# CC1314R10 register map
File version: 1.0
CPU: CM33 1.0, other endian, MPU, FPU, 3 interrupt priority bits
Registers are 32-bit, read-write, reset 0x0 unless marked. A register's access mark holds for its fields unless they carry their own. Offsets are from the block's base; [hi:lo] are bit positions; {n}, {i} and the like mark numbered series; 'fields as' and 'values as' point back to an identical list; <NAME> marks a mode.

## AUX_TIMER2 — AUX Timer2 (AUX_TIMER2) offers flexible: - generation of waveforms and events. - capture of signal period and duty cycle. - generation of single clock pulse. It consists of a: - 16-bit counter. - 4 capture compare channels. - 4 event outputs, which are mapped to AUX event bus, see EVCTL. Each channel subscribes to the asynchronous AUX event bus. They can control one or more event outputs in both capture and compare modes. AUX_SYSIF:TIMER2CLKCTL.SRC selects clock source for the timer.
Base 0x400C3000
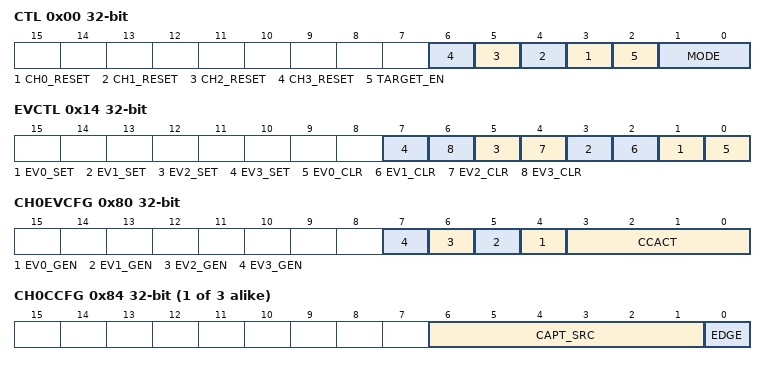
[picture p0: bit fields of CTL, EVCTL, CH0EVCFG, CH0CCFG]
0x00 CTL — Timer Control
  [n+3] CH{n}_RESET (n=0..3) — [{n+3}:{n+3}] Channel {n} reset. 0: No effect. 1: Reset CH{n}CC, CH{n}PCC, CH{n}EVCFG, and CH{n}CCFG. Read returns 0.
  [2] TARGET_EN — [2:2] Select counter target value. You must select TARGET to use shadow target functionality.
    1=TARGET (TARGET.VALUE); 0=CNTR_MAX (65535)
  [1:0] MODE — [1:0] Timer mode control. The timer restarts from 0 when you set MODE to UP_ONCE, UP_PER, or UPDWN_PER. When you write MODE all internally queued updates to [CHnCC.*] and TARGET clear.
    3=UPDWN_PER (Count up and down periodically. The timer counts from 0 to target value and back to 0, repeatedly. Period = (target value * 2) * timer clock period); 2=UP_PER (Count up periodically. The timer increments from 0 to target value, repeatedly. Period = (target value + 1) * timer clock period); 1=UP_ONCE (Count up once. The timer increments from 0 to target value, then stops and sets MODE to DIS.); 0=DIS (Disable timer. Updates to counter, channels, and events stop.)
0x04 TARGET — Target User defined counter target.
  [15:0] VALUE — [15:0] 16 bit user defined counter target value, which is used when selected by CTL.TARGET_EN.
0x08 SHDWTARGET — Shadow Target
  [15:0] VALUE — [15:0] Target value for next counter period. The timer copies VALUE to TARGET.VALUE when CNTR.VALUE becomes 0. The copy does not happen when you restart the timer. This is useful to avoid period jitter in PWM applications with time-varying period, sometimes referenced as phase corrected PWM.
0x0C CNTR — Counter
  [15:0] VALUE ro — [15:0] 16 bit current counter value.
0x10 PRECFG — Clock Prescaler Configuration
  [7:0] CLKDIV — [7:0] Clock division. CLKDIV determines the timer clock frequency for counter, synchronization, and timer event updates. The timer clock frequency is the clock selected by AUX_SYSIF:TIMER2CLKCTL.SRC divided by (CLKDIV + 1). This inverse is the timer clock period. 0x00: Divide by 1. 0x01: Divide by 2. ... 0xFF: Divide by 256.
0x14 EVCTL — Event Control Set and clear individual events manually. Manual update of an event takes priority over automatic channel updates to the same event. You cannot set and clear an event at the same time, such requests will be neglected. An event can be automatically cleared, set, toggled, or pulsed by each channel, listed in decreasing order of priority. The action with highest priority happens when multiple channels want to update an event at the same time. The four events connect to the asynchronous AUX event bus: - Event 0 connects to AUX_EVCTL:EVSTAT3.AUX_TIMER2_EV0. - Event 1 connects to AUX_EVCTL:EVSTAT3.AUX_TIMER2_EV1. - Event 2 connects to AUX_EVCTL:EVSTAT3.AUX_TIMER2_EV2. - Event 3 connects to AUX_EVCTL:EVSTAT3.AUX_TIMER2_EV3.
  [2n+1] EV{n}_SET wo (n=0..3) — [{2n+1}:{2n+1}] Set event {n}. Write 1 to set event {n}.
  [2n] EV{n}_CLR wo (n=0..3) — [{2n}:{2n}] Clear event {n}. Write 1 to clear event {n}.
0x18 PULSETRIG — Pulse Trigger
  [0] TRIG wo — [0:0] Pulse trigger. Write 1 to generate a pulse to AUX_EVCTL:EVSTAT3.AUX_TIMER2_PULSE. Pulse width equals the duty cycle of AUX_SYSIF:TIMER2CLKCTL.SRC.
0x80 CH0EVCFG — Channel 0 Event Configuration This register configures channel function and enables event outputs. Each channel has an edge-detection circuit with memory. The circuit is: - enabled while CCACT selects a capture function and CTL.MODE is different from DIS. - flushed while CCACT selects a capture function and you change CTL.MODE from DIS to another mode. The flush action uses two AUX_SYSIF:TIMER2CLKCTL.SRC clock periods. It prevents capture events caused by expired signal values stored in the edge-detection circuit.
  [n+4] EV{n}_GEN (n=0..3) — [{n+4}:{n+4}] Event {n} enable. 0: Channel 0 does not control event {n}. 1: Channel 0 controls event {n}. When 0 < CCACT < 8, EV{n}_GEN becomes zero after a capture or compare event.
  [3:0] CCACT — [3:0] Capture-Compare action. Capture-Compare action defines 15 different channel functions that utilize capture, compare, and zero events.
    15=PULSE_ON_CMP (Pulse on compare repeatedly. Channel function sequence: - Pulse enabled events when CH0CC.VALUE = CNTR.VALUE. The event is high for two timer clock periods.); 14=TGL_ON_CMP (Toggle on compare repeatedly. Channel function sequence: - Toggle enabled events when CH0CC.VALUE = CNTR.VALUE.); 13=SET_ON_CMP (Set on compare repeatedly. Channel function sequence: - Set enabled events when CH0CC.VALUE = CNTR.VALUE.); 12=CLR_ON_CMP (Clear on compare repeatedly. Channel function sequence: - Clear enabled events when CH0CC.VALUE = CNTR.VALUE.); 11=SET_ON_0_TGL_ON_CMP (Set on zero, toggle on compare repeatedly. Channel function sequence: - Set enabled events when CNTR.VALUE = 0. - Toggle enabled events when CH0CC.VALUE = CNTR.VALUE. Set CTL.MODE to UP_PER for edge-aligned PWM generation. Duty cycle is given by: When CH0CC.VALUE <= TARGET.VALUE: Duty cycle = CH0CC.VALUE / ( TARGET.VALUE + 1 ). When CH0CC.VALUE > TARGET.VALUE: Duty cycle = 1. Enabled events are cleared when CH0CC.VALUE = 0 and CNTR.VALUE = 0.); 10=CLR_ON_0_TGL_ON_CMP (Clear on zero, toggle on compare repeatedly. Channel function sequence: - Clear enabled events when CNTR.VALUE = 0. - Toggle enabled events when CH0CC.VALUE = CNTR.VALUE. Set CTL.MODE to UPDWN_PER for center-aligned PWM generation. Duty cycle is given by: When CH0CC.VALUE <= TARGET.VALUE: Duty cycle = 1 - ( CH0CC.VALUE / TARGET.VALUE ). When CH0CC.VALUE > TARGET.VALUE: Duty cycle = 0. Enabled events are set when CH0CC.VALUE = 0 and CNTR.VALUE = 0.); 9=SET_ON_CAPT (Set on capture repeatedly. Channel function sequence: - Set enabled events on capture event and copy CNTR.VALUE to CH0CC.VALUE. Primary use scenario is to select this function before you start the timer. Follow these steps if you need to select this function while CTL.MODE is different from DIS: - Select this function with no event enable. - Configure CH0CCFG (optional). - Wait for three timer clock periods as defined in PRECFG before you enable events. These steps prevent capture events caused by expired signal values in edge-detection circuit.); 8=PER_PULSE_WIDTH_MEAS (Period and pulse width measurement. Continuously capture period and pulse width of the signal selected by CH0CCFG.CAPT_SRC relative to the signal edge given by CH0CCFG.EDGE. Set enabled events when CH0CC.VALUE contains signal period and CH0PCC.VALUE contains signal pulse width. Notes: - Make sure that you configure CH0CCFG.CAPT_SRC and CCACT when CTL.MODE equals DIS, then set CTL.MODE to UP_ONCE or UP_PER. - The counter restarts in the selected timer mode when CH0CC.VALUE contains the signal period. - If more than one channel uses this function, the channels will perform this function one at a time. The channel with lowest number has priority and performs the function first. Next measurement starts when current measurement completes successfully or times out. A timeout occurs when counter equals target. - If you want to observe a timeout event configure another channel to SET_ON_CAPT. Signal property requirements: - Signal Period >= 2 * ( 1 + PRECFG.CLKDIV ) * timer clock period. - Signal Period <= 65535 * (1 + PRECFG.CLKDIV ) * timer clock period. - Signal low and high phase >= (1 + PRECFG.CLKDIV ) * timer clock period.); 7=PULSE_ON_CMP_DIS (Pulse on compare, and then disable channel. Channel function sequence: - Pulse enabled events when CH0CC.VALUE = CNTR.VALUE. - Disable channel. The event is high for two timer clock periods.); 6=TGL_ON_CMP_DIS (Toggle on compare, and then disable channel. Channel function sequence: - Toggle enabled events when CH0CC.VALUE = CNTR.VALUE. - Disable channel.); 5=SET_ON_CMP_DIS (Set on compare, and then disable channel. Channel function sequence: - Set enabled events when CH0CC.VALUE = CNTR.VALUE. - Disable channel.); 4=CLR_ON_CMP_DIS (Clear on compare, and then disable channel. Channel function sequence: - Clear enabled events when CH0CC.VALUE = CNTR.VALUE. - Disable channel.); 3=SET_ON_0_TGL_ON_CMP_DIS (Set on zero, toggle on compare, and then disable channel. Channel function sequence: - Set enabled events when CNTR.VALUE = 0. - Toggle enabled events when CH0CC.VALUE = CNTR.VALUE. - Disable channel. Enabled events are cleared when CH0CC.VALUE = 0 and CNTR.VALUE = 0.); 2=CLR_ON_0_TGL_ON_CMP_DIS (Clear on zero, toggle on compare, and then disable channel. Channel function sequence: - Clear enabled events when CNTR.VALUE = 0. - Toggle enabled events when CH0CC.VALUE = CNTR.VALUE. - Disable channel. Enabled events are set when CH0CC.VALUE = 0 and CNTR.VALUE = 0.); 1=SET_ON_CAPT_DIS (Set on capture, and then disable channel. Channel function sequence: - Set enabled events on capture event and copy CNTR.VALUE to CH0CC.VALUE. - Disable channel. Primary use scenario is to select this function before you start the timer. Follow these steps if you need to select this function while CTL.MODE is different from DIS: - Set CCACT to SET_ON_CAPT with no event enable. - Configure CH0CCFG (optional). - Wait for three timer clock periods as defined in PRECFG before you set CCACT to SET_ON_CAPT_DIS. Event enable is optional. These steps prevent capture events caused by expired signal values in edge-detection circuit.); 0=DIS (Disable channel.)
{0x84+0x10*i} CH{i}CCFG (i=0..2) — Channel {i} Capture Configuration
  [6:1] CAPT_SRC — [6:1] Select capture signal source from the asynchronous AUX event bus. The selected signal enters the edge-detection circuit. False capture events can occur when: - the edge-detection circuit contains expired signal samples and the circuit is enabled without flush as described in CH{i}EVCFG - this register is reconfigured while CTL.MODE is different from DIS. You can avoid false capture events. When wanted channel function is: - SET_ON_CAPT_DIS, see description for SET_ON_CAPT_DIS in CH{i}EVCFG.CCACT. - SET_ON_CAPT, see description for SET_ON_CAPT in CH{i}EVCFG.CCACT. - PER_PULSE_WIDTH_MEAS, see description for PER_PULSE_WIDTH_MEAS in CH{i}EVCFG.CCACT. If you write a non-enumerated value the behavior is identical to NO_EVENT. The written value is returned when read.
    63=NO_EVENT; 61=AUX_SMPH_AUTOTAKE_DONE (AUX_EVCTL:EVSTAT3.AUX_SMPH_AUTOTAKE_DONE); 60=AUX_ADC_FIFO_NOT_EMPTY (AUX_EVCTL:EVSTAT3.AUX_ADC_FIFO_NOT_EMPTY); 59=AUX_ADC_FIFO_ALMOST_FULL (AUX_EVCTL:EVSTAT3.AUX_ADC_FIFO_ALMOST_FULL); 58=AUX_ADC_IRQ (AUX_EVCTL:EVSTAT3.AUX_ADC_IRQ); 57=AUX_ADC_DONE (AUX_EVCTL:EVSTAT3.AUX_ADC_DONE); 56=AUX_ISRC_RESET_N (AUX_EVCTL:EVSTAT3.AUX_ISRC_RESET_N); 55=AUX_TDC_DONE (AUX_EVCTL:EVSTAT3.AUX_TDC_DONE); 54=AUX_TIMER0_EV (AUX_EVCTL:EVSTAT3.AUX_TIMER0_EV); 53=AUX_TIMER1_EV (AUX_EVCTL:EVSTAT3.AUX_TIMER1_EV); {v}=AUX_TIMER2_EV{v-48} (AUX_EVCTL:EVSTAT3.AUX_TIMER2_EV{v-48}) (v=48..51); 47=AUX_COMPB (AUX_EVCTL:EVSTAT2.AUX_COMPB); 46=AUX_COMPA (AUX_EVCTL:EVSTAT2.AUX_COMPA); 45=MCU_OBSMUX1 (AUX_EVCTL:EVSTAT2.MCU_OBSMUX1); 44=MCU_OBSMUX0 (AUX_EVCTL:EVSTAT2.MCU_OBSMUX0); 43=MCU_EV (AUX_EVCTL:EVSTAT2.MCU_EV); 42=ACLK_REF (AUX_EVCTL:EVSTAT2.ACLK_REF); 41=VDDR_RECHARGE (AUX_EVCTL:EVSTAT2.VDDR_RECHARGE); 40=MCU_ACTIVE (AUX_EVCTL:EVSTAT2.MCU_ACTIVE); 39=PWR_DWN (AUX_EVCTL:EVSTAT2.PWR_DWN); 38=SCLK_LF (AUX_EVCTL:EVSTAT2.SCLK_LF); 37=AON_BATMON_TEMP_UPD (AUX_EVCTL:EVSTAT2.AON_BATMON_TEMP_UPD); 36=AON_BATMON_BAT_UPD (AUX_EVCTL:EVSTAT2.AON_BATMON_BAT_UPD); 35=AON_RTC_4KHZ (AUX_EVCTL:EVSTAT2.AON_RTC_4KHZ); 34=AON_RTC_CH2_DLY (AUX_EVCTL:EVSTAT2.AON_RTC_CH2_DLY); 33=AON_RTC_CH2 (AUX_EVCTL:EVSTAT2.AON_RTC_CH2); 32=MANUAL_EV (AUX_EVCTL:EVSTAT2.MANUAL_EV); {v}=AUXIO{v} (AUX_EVCTL:EVSTAT1.AUXIO{v}) (v=16..31); {v}=AUXIO{v} (AUX_EVCTL:EVSTAT0.AUXIO{v}) (v=0..15)
  [0] EDGE — [0:0] Edge configuration. Channel captures counter value at selected edge on signal source selected by CAPT_SRC. See CH{i}EVCFG.CCACT.
    1=RISING (Capture CNTR.VALUE at rising edge of CAPT_SRC.); 0=FALLING (Capture CNTR.VALUE at falling edge of CAPT_SRC.)
{0x88+0x10*i} CH{i}PCC (i=0..3) — Channel {i} Pipeline Capture Compare
  [15:0] VALUE — [15:0] Pipeline Capture Compare value. 16-bit user defined pipeline compare value or channel-updated capture value. Compare mode: An update of VALUE will be transferred to CH{i}CC.VALUE when the next CNTR.VALUE is zero and CTL.MODE is different from DIS. This is useful for PWM generation and prevents jitter on the edges of the generated signal. Capture mode: When CH{i}EVCFG.CCACT equals PER_PULSE_WIDTH_MEAS then VALUE contains the width of the low or high phase of the selected signal. This is specified by CH{i}CCFG.EDGE and CH{i}CCFG.CAPT_SRC.
{0x8C+0x10*i} CH{i}CC (i=0..3) — Channel {i} Capture Compare
  [15:0] VALUE — [15:0] Capture Compare value. 16-bit user defined compare value or channel-updated capture value. Compare mode: VALUE is compared against CNTR.VALUE and an event is generated as specified by CH{i}EVCFG.CCACT when these are equal. Capture mode: The current counter value is stored in VALUE when a capture event occurs. CH{i}EVCFG.CCACT determines if VALUE is a signal period or a regular capture value.
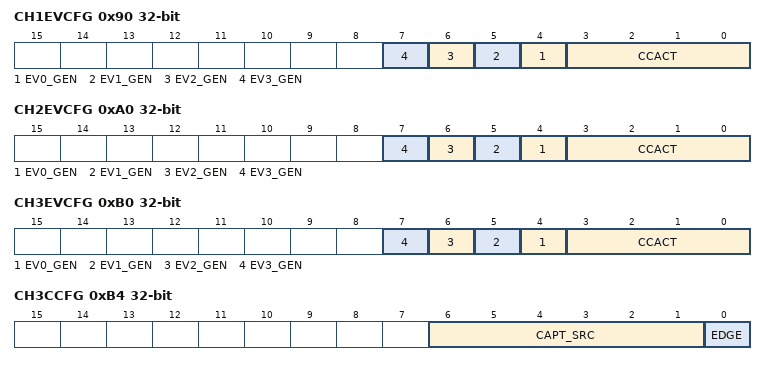
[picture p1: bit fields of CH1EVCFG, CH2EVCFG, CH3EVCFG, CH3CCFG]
0x90 CH1EVCFG — Channel 1 Event Configuration This register configures channel function and enables event outputs. Each channel has an edge-detection circuit with memory. The circuit is: - enabled while CCACT selects a capture function and CTL.MODE is different from DIS. - flushed while CCACT selects a capture function and you change CTL.MODE from DIS to another mode. The flush action uses two AUX_SYSIF:TIMER2CLKCTL.SRC clock periods. It prevents capture events caused by expired signal values stored in the edge-detection circuit.
  [n+4] EV{n}_GEN (n=0..3) — [{n+4}:{n+4}] Event {n} enable. 0: Channel 1 does not control event {n}. 1: Channel 1 controls event {n}. When 0 < CCACT < 8, EV{n}_GEN becomes zero after a capture or compare event.
  [3:0] CCACT — [3:0] Capture-Compare action. Capture-Compare action defines 15 different channel functions that utilize capture, compare, and zero events.
    15=PULSE_ON_CMP (Pulse on compare repeatedly. Channel function sequence: - Pulse enabled events when CH1CC.VALUE = CNTR.VALUE. The event is high for two timer clock periods.); 14=TGL_ON_CMP (Toggle on compare repeatedly. Channel function sequence: - Toggle enabled events when CH1CC.VALUE = CNTR.VALUE.); 13=SET_ON_CMP (Set on compare repeatedly. Channel function sequence: - Set enabled events when CH1CC.VALUE = CNTR.VALUE.); 12=CLR_ON_CMP (Clear on compare repeatedly. Channel function sequence: - Clear enabled events when CH1CC.VALUE = CNTR.VALUE.); 11=SET_ON_0_TGL_ON_CMP (Set on zero, toggle on compare repeatedly. Channel function sequence: - Set enabled events when CNTR.VALUE = 0. - Toggle enabled events when CH1CC.VALUE = CNTR.VALUE. Set CTL.MODE to UP_PER for edge-aligned PWM generation. Duty cycle is given by: When CH1CC.VALUE <= TARGET.VALUE: Duty cycle = CH1CC.VALUE / ( TARGET.VALUE + 1 ). When CH1CC.VALUE > TARGET.VALUE: Duty cycle = 1. Enabled events are cleared when CH1CC.VALUE = 0 and CNTR.VALUE = 0.); 10=CLR_ON_0_TGL_ON_CMP (Clear on zero, toggle on compare repeatedly. Channel function sequence: - Clear enabled events when CNTR.VALUE = 0. - Toggle enabled events when CH1CC.VALUE = CNTR.VALUE. Set CTL.MODE to UPDWN_PER for center-aligned PWM generation. Duty cycle is given by: When CH1CC.VALUE <= TARGET.VALUE: Duty cycle = 1 - ( CH1CC.VALUE / TARGET.VALUE ). When CH1CC.VALUE > TARGET.VALUE: Duty cycle = 0. Enabled events are set when CH1CC.VALUE = 0 and CNTR.VALUE = 0.); 9=SET_ON_CAPT (Set on capture repeatedly. Channel function sequence: - Set enabled events on capture event and copy CNTR.VALUE to CH1CC.VALUE. Primary use scenario is to select this function before you start the timer. Follow these steps if you need to select this function while CTL.MODE is different from DIS: - Select this function with no event enable. - Configure CH1CCFG (optional). - Wait for three timer clock periods as defined in PRECFG before you enable events. These steps prevent capture events caused by expired signal values in edge-detection circuit.); 8=PER_PULSE_WIDTH_MEAS (Period and pulse width measurement. Continuously capture period and pulse width of the signal selected by CH1CCFG.CAPT_SRC relative to the signal edge given by CH1CCFG.EDGE. Set enabled events when CH1CC.VALUE contains signal period and CH1PCC.VALUE contains signal pulse width. Notes: - Make sure that you configure CH1CCFG.CAPT_SRC and CCACT when CTL.MODE equals DIS, then set CTL.MODE to UP_ONCE or UP_PER. - The counter restarts in the selected timer mode when CH1CC.VALUE contains the signal period. - If more than one channel uses this function, the channels will perform this function one at a time. The channel with lowest number has priority and performs the function first. Next measurement starts when current measurement completes successfully or times out. A timeout occurs when counter equals target. - If you want to observe a timeout event configure another channel to SET_ON_CAPT. Signal property requirements: - Signal Period >= 2 * ( 1 + PRECFG.CLKDIV ) * timer clock period. - Signal Period <= 65535 * (1 + PRECFG.CLKDIV ) * timer clock period. - Signal low and high phase >= (1 + PRECFG.CLKDIV ) * timer clock period.); 7=PULSE_ON_CMP_DIS (Pulse on compare, and then disable channel. Channel function sequence: - Pulse enabled events when CH1CC.VALUE = CNTR.VALUE. - Disable channel. The event is high for two timer clock periods.); 6=TGL_ON_CMP_DIS (Toggle on compare, and then disable channel. Channel function sequence: - Toggle enabled events when CH1CC.VALUE = CNTR.VALUE. - Disable channel.); 5=SET_ON_CMP_DIS (Set on compare, and then disable channel. Channel function sequence: - Set enabled events when CH1CC.VALUE = CNTR.VALUE. - Disable channel.); 4=CLR_ON_CMP_DIS (Clear on compare, and then disable channel. Channel function sequence: - Clear enabled events when CH1CC.VALUE = CNTR.VALUE. - Disable channel.); 3=SET_ON_0_TGL_ON_CMP_DIS (Set on zero, toggle on compare, and then disable channel. Channel function sequence: - Set enabled events when CNTR.VALUE = 0. - Toggle enabled events when CH1CC.VALUE = CNTR.VALUE. - Disable channel. Enabled events are cleared when CH1CC.VALUE = 0 and CNTR.VALUE = 0.); 2=CLR_ON_0_TGL_ON_CMP_DIS (Clear on zero, toggle on compare, and then disable channel. Channel function sequence: - Clear enabled events when CNTR.VALUE = 0. - Toggle enabled events when CH1CC.VALUE = CNTR.VALUE. - Disable channel. Enabled events are set when CH1CC.VALUE = 0 and CNTR.VALUE = 0.); 1=SET_ON_CAPT_DIS (Set on capture, and then disable channel. Channel function sequence: - Set enabled events on capture event and copy CNTR.VALUE to CH1CC.VALUE. - Disable channel. Primary use scenario is to select this function before you start the timer. Follow these steps if you need to select this function while CTL.MODE is different from DIS: - Set CCACT to SET_ON_CAPT with no event enable. - Configure CH1CCFG (optional). - Wait for three timer clock periods as defined in PRECFG before you set CCACT to SET_ON_CAPT_DIS. Event enable is optional. These steps prevent capture events caused by expired signal values in edge-detection circuit.); 0=DIS (Disable channel.)
0xA0 CH2EVCFG — Channel 2 Event Configuration This register configures channel function and enables event outputs. Each channel has an edge-detection circuit with memory. The circuit is: - enabled while CCACT selects a capture function and CTL.MODE is different from DIS. - flushed while CCACT selects a capture function and you change CTL.MODE from DIS to another mode. The flush action uses two AUX_SYSIF:TIMER2CLKCTL.SRC clock periods. It prevents capture events caused by expired signal values stored in the edge-detection circuit.
  [n+4] EV{n}_GEN (n=0..3) — [{n+4}:{n+4}] Event {n} enable. 0: Channel 2 does not control event {n}. 1: Channel 2 controls event {n}. When 0 < CCACT < 8, EV{n}_GEN becomes zero after a capture or compare event.
  [3:0] CCACT — [3:0] Capture-Compare action. Capture-Compare action defines 15 different channel functions that utilize capture, compare, and zero events.
    15=PULSE_ON_CMP (Pulse on compare repeatedly. Channel function sequence: - Pulse enabled events when CH2CC.VALUE = CNTR.VALUE. The event is high for two timer clock periods.); 14=TGL_ON_CMP (Toggle on compare repeatedly. Channel function sequence: - Toggle enabled events when CH2CC.VALUE = CNTR.VALUE.); 13=SET_ON_CMP (Set on compare repeatedly. Channel function sequence: - Set enabled events when CH2CC.VALUE = CNTR.VALUE.); 12=CLR_ON_CMP (Clear on compare repeatedly. Channel function sequence: - Clear enabled events when CH2CC.VALUE = CNTR.VALUE.); 11=SET_ON_0_TGL_ON_CMP (Set on zero, toggle on compare repeatedly. Channel function sequence: - Set enabled events when CNTR.VALUE = 0. - Toggle enabled events when CH2CC.VALUE = CNTR.VALUE. Set CTL.MODE to UP_PER for edge-aligned PWM generation. Duty cycle is given by: When CH2CC.VALUE <= TARGET.VALUE: Duty cycle = CH2CC.VALUE / ( TARGET.VALUE + 1 ). When CH2CC.VALUE > TARGET.VALUE: Duty cycle = 1. Enabled events are cleared when CH2CC.VALUE = 0 and CNTR.VALUE = 0.); 10=CLR_ON_0_TGL_ON_CMP (Clear on zero, toggle on compare repeatedly. Channel function sequence: - Clear enabled events when CNTR.VALUE = 0. - Toggle enabled events when CH2CC.VALUE = CNTR.VALUE. Set CTL.MODE to UPDWN_PER for center-aligned PWM generation. Duty cycle is given by: When CH2CC.VALUE <= TARGET.VALUE: Duty cycle = 1 - ( CH2CC.VALUE / TARGET.VALUE ). When CH2CC.VALUE > TARGET.VALUE: Duty cycle = 0. Enabled events are set when CH2CC.VALUE = 0 and CNTR.VALUE = 0.); 9=SET_ON_CAPT (Set on capture repeatedly. Channel function sequence: - Set enabled events on capture event and copy CNTR.VALUE to CH2CC.VALUE. Primary use scenario is to select this function before you start the timer. Follow these steps if you need to select this function while CTL.MODE is different from DIS: - Select this function with no event enable. - Configure CH2CCFG (optional). - Wait for three timer clock periods as defined in PRECFG before you enable events. These steps prevent capture events caused by expired signal values in edge-detection circuit.); 8=PER_PULSE_WIDTH_MEAS (Period and pulse width measurement. Continuously capture period and pulse width of the signal selected by CH2CCFG.CAPT_SRC relative to the signal edge given by CH2CCFG.EDGE. Set enabled events when CH2CC.VALUE contains signal period and CH2PCC.VALUE contains signal pulse width. Notes: - Make sure that you configure CH2CCFG.CAPT_SRC and CCACT when CTL.MODE equals DIS, then set CTL.MODE to UP_ONCE or UP_PER. - The counter restarts in the selected timer mode when CH2CC.VALUE contains the signal period. - If more than one channel uses this function, the channels will perform this function one at a time. The channel with lowest number has priority and performs the function first. Next measurement starts when current measurement completes successfully or times out. A timeout occurs when counter equals target. - If you want to observe a timeout event configure another channel to SET_ON_CAPT. Signal property requirements: - Signal Period >= 2 * ( 1 + PRECFG.CLKDIV ) * timer clock period. - Signal Period <= 65535 * (1 + PRECFG.CLKDIV ) * timer clock period. - Signal low and high phase >= (1 + PRECFG.CLKDIV ) * timer clock period.); 7=PULSE_ON_CMP_DIS (Pulse on compare, and then disable channel. Channel function sequence: - Pulse enabled events when CH2CC.VALUE = CNTR.VALUE. - Disable channel. The event is high for two timer clock periods.); 6=TGL_ON_CMP_DIS (Toggle on compare, and then disable channel. Channel function sequence: - Toggle enabled events when CH2CC.VALUE = CNTR.VALUE. - Disable channel.); 5=SET_ON_CMP_DIS (Set on compare, and then disable channel. Channel function sequence: - Set enabled events when CH2CC.VALUE = CNTR.VALUE. - Disable channel.); 4=CLR_ON_CMP_DIS (Clear on compare, and then disable channel. Channel function sequence: - Clear enabled events when CH2CC.VALUE = CNTR.VALUE. - Disable channel.); 3=SET_ON_0_TGL_ON_CMP_DIS (Set on zero, toggle on compare, and then disable channel. Channel function sequence: - Set enabled events when CNTR.VALUE = 0. - Toggle enabled events when CH2CC.VALUE = CNTR.VALUE. - Disable channel. Enabled events are cleared when CH2CC.VALUE = 0 and CNTR.VALUE = 0.); 2=CLR_ON_0_TGL_ON_CMP_DIS (Clear on zero, toggle on compare, and then disable channel. Channel function sequence: - Clear enabled events when CNTR.VALUE = 0. - Toggle enabled events when CH2CC.VALUE = CNTR.VALUE. - Disable channel. Enabled events are set when CH2CC.VALUE = 0 and CNTR.VALUE = 0.); 1=SET_ON_CAPT_DIS (Set on capture, and then disable channel. Channel function sequence: - Set enabled events on capture event and copy CNTR.VALUE to CH2CC.VALUE. - Disable channel. Primary use scenario is to select this function before you start the timer. Follow these steps if you need to select this function while CTL.MODE is different from DIS: - Set to SET_ON_CAPT with no event enable. - Configure CH2CCFG (optional). - Wait for three timer clock periods as defined in PRECFG before you set to SET_ON_CAPT_DIS. Event enable is optional. These steps prevent capture events caused by expired signal values in edge-detection circuit.); 0=DIS (Disable channel.)
0xB0 CH3EVCFG — Channel 3 Event Configuration This register configures channel function and enables event outputs. Each channel has an edge-detection circuit with memory. The circuit is: - enabled while CCACT selects a capture function and CTL.MODE is different from DIS. - flushed while CCACT selects a capture function and you change CTL.MODE from DIS to another mode. The flush action uses two AUX_SYSIF:TIMER2CLKCTL.SRC clock periods. It prevents capture events caused by expired signal values stored in the edge-detection circuit.
  [n+4] EV{n}_GEN (n=0..3) — [{n+4}:{n+4}] Event {n} enable. 0: Channel 3 does not control event {n}. 1: Channel 3 controls event {n}. When 0 < CCACT < 8, EV{n}_GEN becomes zero after a capture or compare event.
  [3:0] CCACT — [3:0] Capture-Compare action. Capture-Compare action defines 15 different channel functions that utilize capture, compare, and zero events.
    15=PULSE_ON_CMP (Pulse on compare repeatedly. Channel function sequence: - Pulse enabled events when CH3CC.VALUE = CNTR.VALUE. The event is high for two timer clock periods.); 14=TGL_ON_CMP (Toggle on compare repeatedly. Channel function sequence: - Toggle enabled events when CH3CC.VALUE = CNTR.VALUE.); 13=SET_ON_CMP (Set on compare repeatedly. Channel function sequence: - Set enabled events when CH3CC.VALUE = CNTR.VALUE.); 12=CLR_ON_CMP (Clear on compare repeatedly. Channel function sequence: - Clear enabled events when CH3CC.VALUE = CNTR.VALUE.); 11=SET_ON_0_TGL_ON_CMP (Set on zero, toggle on compare repeatedly. Channel function sequence: - Set enabled events when CNTR.VALUE = 0. - Toggle enabled events when CH3CC.VALUE = CNTR.VALUE. Set CTL.MODE to UP_PER for edge-aligned PWM generation. Duty cycle is given by: When CH3CC.VALUE <= TARGET.VALUE: Duty cycle = CH3CC.VALUE / ( TARGET.VALUE + 1 ). When CH3CC.VALUE > TARGET.VALUE: Duty cycle = 1. Enabled events are cleared when CH3CC.VALUE = 0 and CNTR.VALUE = 0.); 10=CLR_ON_0_TGL_ON_CMP (Clear on zero, toggle on compare repeatedly. Channel function sequence: - Clear enabled events when CNTR.VALUE = 0. - Toggle enabled events when CH3CC.VALUE = CNTR.VALUE. Set CTL.MODE to UPDWN_PER for center-aligned PWM generation. Duty cycle is given by: When CH3CC.VALUE <= TARGET.VALUE: Duty cycle = 1 - ( CH3CC.VALUE / TARGET.VALUE ). When CH3CC.VALUE > TARGET.VALUE: Duty cycle = 0. Enabled events are set when CH3CC.VALUE = 0 and CNTR.VALUE = 0.); 9=SET_ON_CAPT (Set on capture repeatedly. Channel function sequence: - Set enabled events on capture event and copy CNTR.VALUE to CH3CC.VALUE. Primary use scenario is to select this function before you start the timer. Follow these steps if you need to select this function while CTL.MODE is different from DIS: - Select this function with no event enable. - Configure CH3CCFG (optional). - Wait for three timer clock periods as defined in PRECFG before you enable events. These steps prevent capture events caused by expired signal values in edge-detection circuit.); 8=PER_PULSE_WIDTH_MEAS (Period and pulse width measurement. Continuously capture period and pulse width of the signal selected by CH3CCFG.CAPT_SRC relative to the signal edge given by CH3CCFG.EDGE. Set enabled events when CH3CC.VALUE contains signal period and CH3PCC.VALUE contains signal pulse width. Notes: - Make sure that you configure CH3CCFG.CAPT_SRC and CCACT when CTL.MODE equals DIS, then set CTL.MODE to UP_ONCE or UP_PER. - The counter restarts in the selected timer mode when CH3CC.VALUE contains the signal period. - If more than one channel uses this function, the channels will perform this function one at a time. The channel with lowest number has priority and performs the function first. Next measurement starts when current measurement completes successfully or times out. A timeout occurs when counter equals target. - If you want to observe a timeout event configure another channel to SET_ON_CAPT. Signal property requirements: - Signal Period >= 2 * ( 1 + PRECFG.CLKDIV ) * timer clock period. - Signal Period <= 65535 * (1 + PRECFG.CLKDIV ) * timer clock period. - Signal low and high phase >= (1 + PRECFG.CLKDIV ) * timer clock period.); 7=PULSE_ON_CMP_DIS (Pulse on compare, and then disable channel. Channel function sequence: - Pulse enabled events when CH3CC.VALUE = CNTR.VALUE. - Disable channel. The event is high for two timer clock periods.); 6=TGL_ON_CMP_DIS (Toggle on compare, and then disable channel. Channel function sequence: - Toggle enabled events when CH3CC.VALUE = CNTR.VALUE. - Disable channel.); 5=SET_ON_CMP_DIS (Set on compare, and then disable channel. Channel function sequence: - Set enabled events when CH3CC.VALUE = CNTR.VALUE. - Disable channel.); 4=CLR_ON_CMP_DIS (Clear on compare, and then disable channel. Channel function sequence: - Clear enabled events when CH3CC.VALUE = CNTR.VALUE. - Disable channel.); 3=SET_ON_0_TGL_ON_CMP_DIS (Set on zero, toggle on compare, and then disable channel. Channel function sequence: - Set enabled events when CNTR.VALUE = 0. - Toggle enabled events when CH3CC.VALUE = CNTR.VALUE. - Disable channel. Enabled events are cleared when CH3CC.VALUE = 0 and CNTR.VALUE = 0.); 2=CLR_ON_0_TGL_ON_CMP_DIS (Clear on zero, toggle on compare, and then disable channel. Channel function sequence: - Clear enabled events when CNTR.VALUE = 0. - Toggle enabled events when CH3CC.VALUE = CNTR.VALUE. - Disable channel. Enabled events are set when CH3CC.VALUE = 0 and CNTR.VALUE = 0.); 1=SET_ON_CAPT_DIS (Set on capture, and then disable channel. Channel function sequence: - Set enabled events on capture event and copy CNTR.VALUE to CH3CC.VALUE. - Disable channel. Primary use scenario is to select this function before you start the timer. Follow these steps if you need to select this function while CTL.MODE is different from DIS: - Set CCACT to SET_ON_CAPT with no event enable. - Configure CH3CCFG (optional). - Wait for three timer clock periods as defined in PRECFG before you set CCACT to SET_ON_CAPT_DIS. Event enable is optional. These steps prevent capture events caused by expired signal values in edge-detection circuit.); 0=DIS (Disable channel.)
0xB4 CH3CCFG — Channel 3 Capture Configuration
  [6:1] CAPT_SRC — [6:1] Select capture signal source from the asynchronous AUX event bus. The selected signal enters the edge-detection circuit. False capture events can occur when: - the edge-detection circuit contains expired signal samples and the circuit is enabled without flush as described in CH3EVCFG - this register is reconfigured while CTL.MODE is different from DIS. You can avoid false capture events. When wanted channel function: - SET_ON_CAPT_DIS, see description for SET_ON_CAPT_DIS in CH3EVCFG.CCACT. - SET_ON_CAPT, see description for SET_ON_CAPT in CH3EVCFG.CCACT. - PER_PULSE_WIDTH_MEAS, see description for PER_PULSE_WIDTH_MEAS in CH3EVCFG.CCACT. If you write a non-enumerated value the behavior is identical to NO_EVENT. The written value is returned when read.
    values as CH0CCFG.CAPT_SRC
  [0] EDGE — [0:0] Edge configuration. Channel captures counter value at selected edge on signal source selected by CAPT_SRC. See CH3EVCFG.CCACT.
    values as CH0CCFG.EDGE
